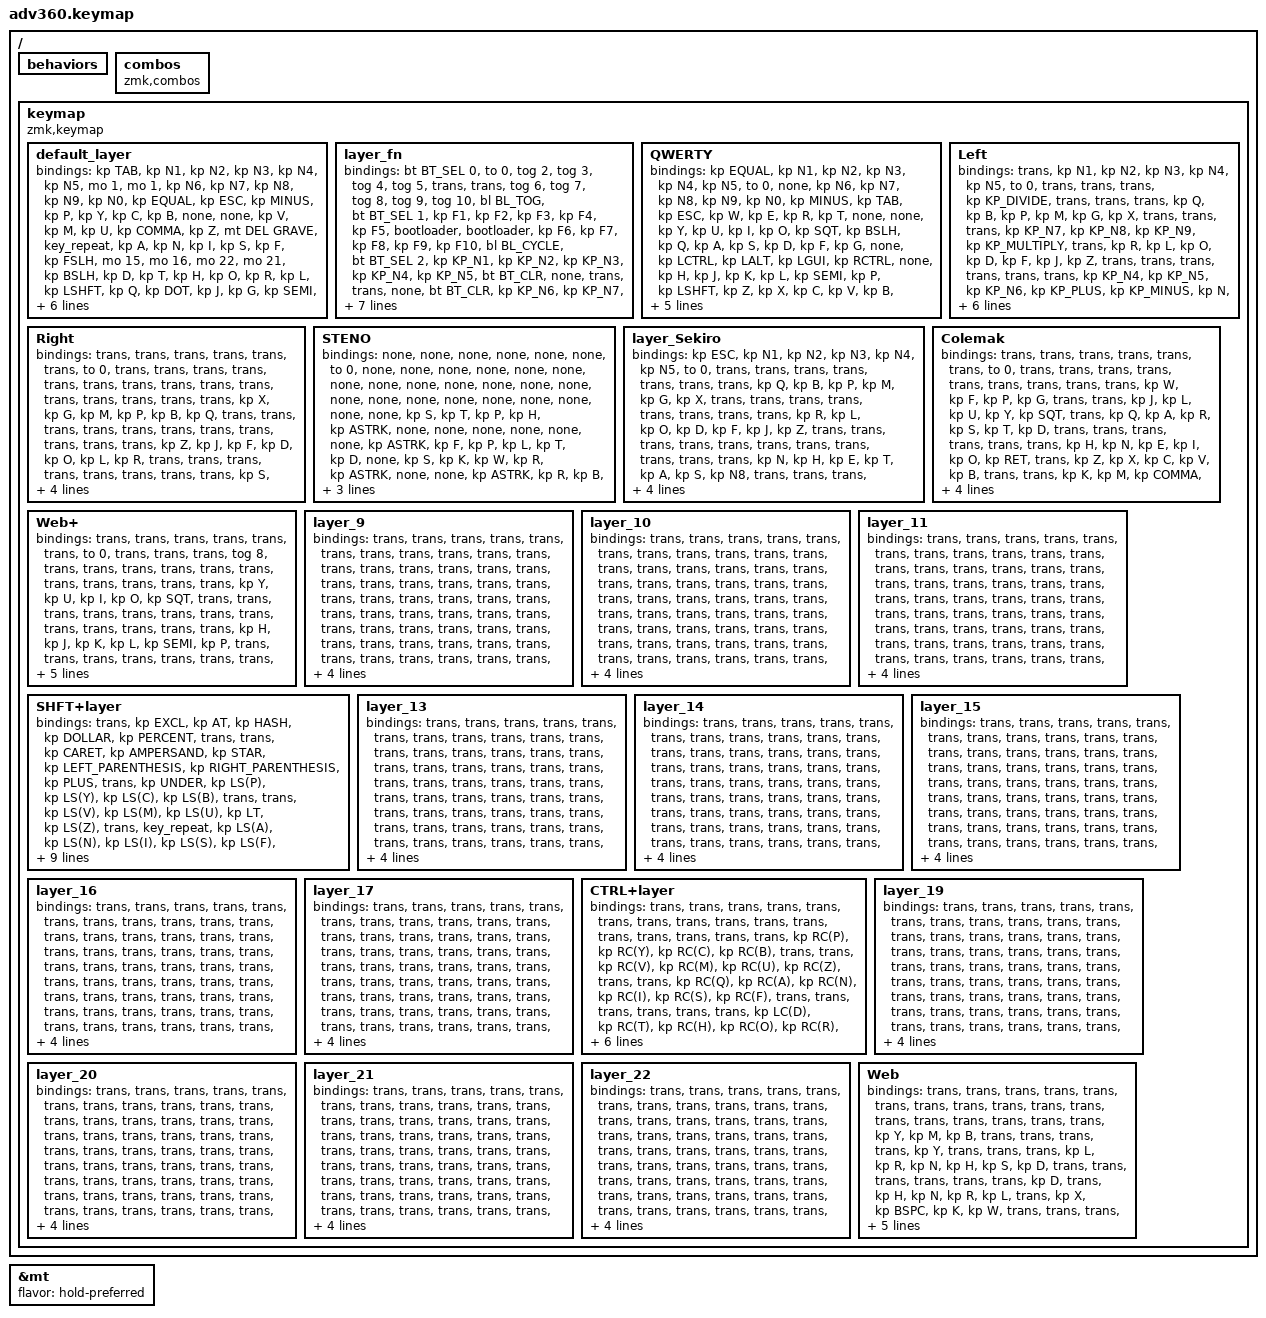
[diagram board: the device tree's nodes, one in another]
/*
 * Copyright (c) 2020 The ZMK Contributors
 *
 * SPDX-License-Identifier: MIT
 */
/* THIS FILE WAS GENERATED!
 *
 * This file was generated automatically. You may or may not want to
 * edit it directly.
 */

#include <behaviors.dtsi>
#include <dt-bindings/zmk/backlight.h>
#include <dt-bindings/zmk/bt.h>
#include <dt-bindings/zmk/keys.h>
#include <dt-bindings/zmk/rgb.h>

&mt { flavor = "hold-preferred"; };

/ {
    behaviors {
        #include "macros.dtsi"
    };

    combos { compatible = "zmk,combos"; };

    keymap {
        compatible = "zmk,keymap";

        default_layer {
            bindings = <
&kp TAB      &kp N1     &kp N2     &kp N3     &kp N4  &kp N5    &mo 1                                                                  &mo 1      &kp N6            &kp N7    &kp N8  &kp N9         &kp N0     &kp EQUAL
&kp ESC      &kp MINUS  &kp P      &kp Y      &kp C   &kp B     &none                                                                  &none      &kp V             &kp M     &kp U   &kp COMMA      &kp Z      &mt DEL GRAVE
&key_repeat  &kp A      &kp N      &kp I      &kp S   &kp F     &kp FSLH  &mo 15           &mo 16           &mo 22       &mo 21        &kp BSLH   &kp D             &kp T     &kp H   &kp O          &kp R      &kp L
&kp LSHFT    &kp Q      &kp DOT    &kp J      &kp G   &kp SEMI                             &mo 14           &lt 20 LBKT                           &kp SINGLE_QUOTE  &kp W     &kp K   &kp BACKSPACE  &kp X      &kp HOME
&kp LCTRL    &none      &kp PG_DN  &kp PG_UP  &none             &kp E     &lt 12 QUESTION  &lt 13 EXCL      &lt 19 RBKT  &lt 18 ENTER  &kp SPACE                    &kp LEFT  &kp UP  &kp DOWN       &kp RIGHT  &kp END
            >;
        };

        layer_fn {
            bindings = <
&bt BT_SEL 0  &to 0      &tog 2     &tog 3     &tog 4     &tog 5     &trans                                           &trans       &tog 6     &tog 7     &tog 8     &tog 9     &tog 10    &bl BL_TOG
&bt BT_SEL 1  &kp F1     &kp F2     &kp F3     &kp F4     &kp F5     &bootloader                                      &bootloader  &kp F6     &kp F7     &kp F8     &kp F9     &kp F10    &bl BL_CYCLE
&bt BT_SEL 2  &kp KP_N1  &kp KP_N2  &kp KP_N3  &kp KP_N4  &kp KP_N5  &bt BT_CLR   &none   &trans      &trans  &none   &bt BT_CLR   &kp KP_N6  &kp KP_N7  &kp KP_N8  &kp KP_N9  &kp KP_N0  &rgb_ug RGB_TOG
&bt BT_SEL 3  &kp F11    &kp F12    &kp F13    &kp F14    &kp F15                         &trans      &trans                       &kp F16    &kp F17    &kp F18    &kp F19    &kp F20    &trans
&bt BT_SEL 4  &kp F21    &kp F22    &kp F23    &kp F24               &trans       &trans  &trans      &trans  &trans  &trans                  &trans     &trans     &trans     &trans     &trans
            >;
        };

        QWERTY {
            bindings = <
&kp EQUAL  &kp N1     &kp N2    &kp N3    &kp N4     &kp N5  &to 0                                                    &none      &kp N6  &kp N7  &kp N8     &kp N9      &kp N0    &kp MINUS
&kp TAB    &kp ESC    &kp W     &kp E     &kp R      &kp T   &none                                                    &none      &kp Y   &kp U   &kp I      &kp O       &kp SQT   &kp BSLH
&kp Q      &kp A      &kp S     &kp D     &kp F      &kp G   &none     &kp LCTRL  &kp LALT      &kp LGUI   &kp RCTRL  &none      &kp H   &kp J   &kp K      &kp L       &kp SEMI  &kp P
&kp LSHFT  &kp Z      &kp X     &kp C     &kp V      &kp B                        &kp HOME      &kp PG_UP                        &kp N   &kp M   &kp COMMA  &kp DOT     &kp FSLH  &kp RSHFT
&trans     &kp GRAVE  &kp CAPS  &kp LEFT  &kp RIGHT          &kp BSPC  &kp DEL    &kp END       &kp PG_DN  &kp ENTER  &kp KP_N0          &kp UP  &kp DOWN   &kp KP_DOT  &kp RBKT  &trans
            >;
        };

        Left {
            bindings = <
&trans  &kp N1  &kp N2  &kp N3  &kp N4  &kp N5  &to 0                                                     &trans  &trans      &trans           &kp KP_DIVIDE  &trans      &trans           &trans
&kp Q   &kp B   &kp P   &kp M   &kp G   &kp X   &trans                                                    &trans  &trans      &kp KP_N7        &kp KP_N8      &kp KP_N9   &kp KP_MULTIPLY  &trans
&kp R   &kp L   &kp O   &kp D   &kp F   &kp J   &kp Z            &trans  &trans           &trans  &trans  &trans  &trans      &kp KP_N4        &kp KP_N5      &kp KP_N6   &kp KP_PLUS      &kp KP_MINUS
&kp N   &kp H   &kp E   &kp T   &kp A   &kp S                            &trans           &trans                  &kp KP_NUM  &kp KP_NUMBER_1  &kp KP_N2      &kp KP_N3   &kp KP_ENTER     &trans
&kp V   &kp W   &kp K   &kp C   &kp Y           &mt LSHFT SPACE  &kp I   &mt LCTRL U      &trans  &trans  &trans              &kp KP_N0        &trans         &kp KP_DOT  &trans           &trans
            >;
        };

        Right {
            bindings = <
&trans  &trans  &trans  &trans  &trans  &trans  &to 0                                                 &trans           &trans  &trans  &trans  &trans  &trans  &trans
&trans  &trans  &trans  &trans  &trans  &trans  &trans                                                &trans           &kp X   &kp G   &kp M   &kp P   &kp B   &kp Q
&trans  &trans  &trans  &trans  &trans  &trans  &trans  &trans  &trans      &trans       &trans       &kp Z            &kp J   &kp F   &kp D   &kp O   &kp L   &kp R
&trans  &trans  &trans  &trans  &trans  &trans                  &trans      &trans                                     &kp S   &kp A   &kp T   &kp E   &kp H   &kp N
&trans  &trans  &trans  &trans  &trans          &trans  &trans  &trans      &mt LCTRL U  &mt LSHFT I  &mt ENTER SPACE          &kp Y   &kp C   &kp K   &kp W   &kp V
            >;
        };

        STENO {
            bindings = <
&none  &none  &none  &none  &none  &none      &to 0                                  &none  &none      &none  &none  &none  &none  &none
&none  &none  &none  &none  &none  &none      &none                                  &none  &none      &none  &none  &none  &none  &none
&none  &kp S  &kp T  &kp P  &kp H  &kp ASTRK  &none  &none  &none      &none  &none  &none  &kp ASTRK  &kp F  &kp P  &kp L  &kp T  &kp D
&none  &kp S  &kp K  &kp W  &kp R  &kp ASTRK                &none      &none                &kp ASTRK  &kp R  &kp B  &kp G  &kp S  &kp Z
&none  &none  &none  &none  &none             &kp A  &kp O  &none      &none  &kp E  &kp U             &none  &none  &none  &none  &trans
            >;
        };

        layer_Sekiro {
            bindings = <
&kp ESC  &kp N1  &kp N2  &kp N3  &kp N4  &kp N5  &to 0                                          &trans  &trans  &trans  &trans  &trans  &trans  &trans
&kp Q    &kp B   &kp P   &kp M   &kp G   &kp X   &trans                                         &trans  &trans  &trans  &trans  &trans  &trans  &trans
&kp R    &kp L   &kp O   &kp D   &kp F   &kp J   &kp Z      &trans  &trans      &trans  &trans  &trans  &trans  &trans  &trans  &trans  &trans  &trans
&kp N    &kp H   &kp E   &kp T   &kp A   &kp S                      &kp N8      &trans                  &trans  &trans  &trans  &trans  &trans  &trans
&kp V    &kp W   &kp K   &kp C   &kp Y           &kp SPACE  &kp I   &kp U       &trans  &trans  &trans          &trans  &trans  &trans  &trans  &trans
            >;
        };

        Colemak {
            bindings = <
&trans  &trans  &trans  &trans  &trans  &trans  &to 0                                       &trans  &trans  &trans  &trans     &trans   &trans    &trans
&trans  &trans  &kp W   &kp F   &kp P   &kp G   &trans                                      &trans  &kp J   &kp L   &kp U      &kp Y    &kp SQT   &trans
&kp Q   &kp A   &kp R   &kp S   &kp T   &kp D   &trans  &trans  &trans      &trans  &trans  &trans  &kp H   &kp N   &kp E      &kp I    &kp O     &kp RET
&trans  &kp Z   &kp X   &kp C   &kp V   &kp B                   &trans      &trans                  &kp K   &kp M   &kp COMMA  &kp DOT  &kp SEMI  &trans
&trans  &trans  &trans  &trans  &trans          &trans  &trans  &trans      &trans  &trans  &trans          &trans  &trans     &trans   &trans    &trans
            >;
        };

        Web+ {
            bindings = <
&trans  &trans  &trans  &trans  &trans  &trans  &to 0                                       &trans  &trans    &trans           &tog 8        &trans         &trans       &trans
&trans  &trans  &trans  &trans  &trans  &trans  &trans                                      &trans  &kp Y     &kp U            &kp I         &kp O          &kp SQT      &trans
&trans  &trans  &trans  &trans  &trans  &trans  &trans  &trans  &trans      &trans  &trans  &trans  &kp H     &kp J            &kp K         &kp L          &kp SEMI     &kp P
&trans  &trans  &trans  &trans  &trans  &trans                  &trans      &trans                  &kp HOME  &kp LC(W)        &kp PG_UP     &kp PG_DN      &kp END      &kp LC(LS(T))
&trans  &trans  &trans  &trans  &trans          &trans  &trans  &trans      &trans  &trans  &trans            &kp LC(LS(TAB))  &kp LA(LEFT)  &kp LA(RIGHT)  &kp LC(TAB)  &trans
            >;
        };

        layer_9 {
            bindings = <
&trans  &trans  &trans  &trans  &trans  &trans  &trans                                      &trans  &trans  &trans  &trans  &trans  &trans  &trans
&trans  &trans  &trans  &trans  &trans  &trans  &trans                                      &trans  &trans  &trans  &trans  &trans  &trans  &trans
&trans  &trans  &trans  &trans  &trans  &trans  &trans  &trans  &trans      &trans  &trans  &trans  &trans  &trans  &trans  &trans  &trans  &trans
&trans  &trans  &trans  &trans  &trans  &trans                  &trans      &trans                  &trans  &trans  &trans  &trans  &trans  &trans
&trans  &trans  &trans  &trans  &trans          &trans  &trans  &trans      &trans  &trans  &trans          &trans  &trans  &trans  &trans  &trans
            >;
        };

        layer_10 {
            bindings = <
&trans  &trans  &trans  &trans  &trans  &trans  &trans                                      &trans  &trans  &trans  &trans  &trans  &trans  &trans
&trans  &trans  &trans  &trans  &trans  &trans  &trans                                      &trans  &trans  &trans  &trans  &trans  &trans  &trans
&trans  &trans  &trans  &trans  &trans  &trans  &trans  &trans  &trans      &trans  &trans  &trans  &trans  &trans  &trans  &trans  &trans  &trans
&trans  &trans  &trans  &trans  &trans  &trans                  &trans      &trans                  &trans  &trans  &trans  &trans  &trans  &trans
&trans  &trans  &trans  &trans  &trans          &trans  &trans  &trans      &trans  &trans  &trans          &trans  &trans  &trans  &trans  &trans
            >;
        };

        layer_11 {
            bindings = <
&trans  &trans  &trans  &trans  &trans  &trans  &trans                                      &trans  &trans  &trans  &trans  &trans  &trans  &trans
&trans  &trans  &trans  &trans  &trans  &trans  &trans                                      &trans  &trans  &trans  &trans  &trans  &trans  &trans
&trans  &trans  &trans  &trans  &trans  &trans  &trans  &trans  &trans      &trans  &trans  &trans  &trans  &trans  &trans  &trans  &trans  &trans
&trans  &trans  &trans  &trans  &trans  &trans                  &trans      &trans                  &trans  &trans  &trans  &trans  &trans  &trans
&trans  &trans  &trans  &trans  &trans          &trans  &trans  &trans      &trans  &trans  &trans          &trans  &trans  &trans  &trans  &trans
            >;
        };

        SHFT+layer {
            bindings = <
&trans       &kp EXCL   &kp AT     &kp HASH   &kp DOLLAR  &kp PERCENT  &trans                                                   &trans    &kp CARET          &kp AMPERSAND  &kp STAR   &kp LEFT_PARENTHESIS  &kp RIGHT_PARENTHESIS  &kp PLUS
&trans       &kp UNDER  &kp LS(P)  &kp LS(Y)  &kp LS(C)   &kp LS(B)    &trans                                                   &trans    &kp LS(V)          &kp LS(M)      &kp LS(U)  &kp LT                &kp LS(Z)              &trans
&key_repeat  &kp LS(A)  &kp LS(N)  &kp LS(I)  &kp LS(S)   &kp LS(F)    &kp LS(NON_US_BSLH)  &trans  &trans      &trans  &trans  &kp PIPE  &kp LS(D)          &kp LS(T)      &kp LS(H)  &kp LS(O)             &kp LS(R)              &kp LS(L)
&trans       &kp LS(Q)  &kp GT     &kp LS(J)  &kp LS(G)   &kp COLON                                 &trans      &trans                    &kp DOUBLE_QUOTES  &kp LS(W)      &kp LS(K)  &kp BSPC              &kp LS(X)              &trans
&trans       &trans     &trans     &trans     &trans                   &trans               &trans  &trans      &trans  &trans  &trans                       &trans         &trans     &trans                &trans                 &trans
            >;
        };

        layer_13 {
            bindings = <
&trans  &trans  &trans  &trans  &trans  &trans  &trans                                      &trans  &trans  &trans  &trans  &trans  &trans  &trans
&trans  &trans  &trans  &trans  &trans  &trans  &trans                                      &trans  &trans  &trans  &trans  &trans  &trans  &trans
&trans  &trans  &trans  &trans  &trans  &trans  &trans  &trans  &trans      &trans  &trans  &trans  &trans  &trans  &trans  &trans  &trans  &trans
&trans  &trans  &trans  &trans  &trans  &trans                  &trans      &trans                  &trans  &trans  &trans  &trans  &trans  &trans
&trans  &trans  &trans  &trans  &trans          &trans  &trans  &trans      &trans  &trans  &trans          &trans  &trans  &trans  &trans  &trans
            >;
        };

        layer_14 {
            bindings = <
&trans  &trans  &trans  &trans  &trans  &trans  &trans                                      &trans  &trans  &trans  &trans  &trans  &trans  &trans
&trans  &trans  &trans  &trans  &trans  &trans  &trans                                      &trans  &trans  &trans  &trans  &trans  &trans  &trans
&trans  &trans  &trans  &trans  &trans  &trans  &trans  &trans  &trans      &trans  &trans  &trans  &trans  &trans  &trans  &trans  &trans  &trans
&trans  &trans  &trans  &trans  &trans  &trans                  &trans      &trans                  &trans  &trans  &trans  &trans  &trans  &trans
&trans  &trans  &trans  &trans  &trans          &trans  &trans  &trans      &trans  &trans  &trans          &trans  &trans  &trans  &trans  &trans
            >;
        };

        layer_15 {
            bindings = <
&trans  &trans  &trans  &trans  &trans  &trans  &trans                                      &trans  &trans  &trans  &trans  &trans  &trans  &trans
&trans  &trans  &trans  &trans  &trans  &trans  &trans                                      &trans  &trans  &trans  &trans  &trans  &trans  &trans
&trans  &trans  &trans  &trans  &trans  &trans  &trans  &trans  &trans      &trans  &trans  &trans  &trans  &trans  &trans  &trans  &trans  &trans
&trans  &trans  &trans  &trans  &trans  &trans                  &trans      &trans                  &trans  &trans  &trans  &trans  &trans  &trans
&trans  &trans  &trans  &trans  &trans          &trans  &trans  &trans      &trans  &trans  &trans          &trans  &trans  &trans  &trans  &trans
            >;
        };

        layer_16 {
            bindings = <
&trans  &trans  &trans  &trans  &trans  &trans  &trans                                      &trans  &trans  &trans  &trans  &trans  &trans  &trans
&trans  &trans  &trans  &trans  &trans  &trans  &trans                                      &trans  &trans  &trans  &trans  &trans  &trans  &trans
&trans  &trans  &trans  &trans  &trans  &trans  &trans  &trans  &trans      &trans  &trans  &trans  &trans  &trans  &trans  &trans  &trans  &trans
&trans  &trans  &trans  &trans  &trans  &trans                  &trans      &trans                  &trans  &trans  &trans  &trans  &trans  &trans
&trans  &trans  &trans  &trans  &trans          &trans  &trans  &trans      &trans  &trans  &trans          &trans  &trans  &trans  &trans  &trans
            >;
        };

        layer_17 {
            bindings = <
&trans  &trans  &trans  &trans  &trans  &trans  &trans                                      &trans  &trans  &trans  &trans  &trans  &trans  &trans
&trans  &trans  &trans  &trans  &trans  &trans  &trans                                      &trans  &trans  &trans  &trans  &trans  &trans  &trans
&trans  &trans  &trans  &trans  &trans  &trans  &trans  &trans  &trans      &trans  &trans  &trans  &trans  &trans  &trans  &trans  &trans  &trans
&trans  &trans  &trans  &trans  &trans  &trans                  &trans      &trans                  &trans  &trans  &trans  &trans  &trans  &trans
&trans  &trans  &trans  &trans  &trans          &trans  &trans  &trans      &trans  &trans  &trans          &trans  &trans  &trans  &trans  &trans
            >;
        };

        CTRL+layer {
            bindings = <
&trans     &trans         &trans       &trans     &trans     &trans        &trans                                      &trans  &trans     &trans     &trans     &trans     &trans     &trans
&trans     &trans         &kp RC(P)    &kp RC(Y)  &kp RC(C)  &kp RC(B)     &trans                                      &trans  &kp RC(V)  &kp RC(M)  &kp RC(U)  &kp RC(Z)  &trans     &trans
&kp RC(Q)  &kp RC(A)      &kp RC(N)    &kp RC(I)  &kp RC(S)  &kp RC(F)     &trans  &trans  &trans      &trans  &trans  &trans  &kp LC(D)  &kp RC(T)  &kp RC(H)  &kp RC(O)  &kp RC(R)  &kp RC(L)
&trans     &kp RC(COMMA)  &kp RC(DOT)  &kp RC(J)  &kp RC(G)  &kp RC(SEMI)                  &trans      &trans                  &trans     &kp RC(W)  &kp RC(K)  &trans     &kp RC(X)  &trans
&trans     &trans         &trans       &trans     &trans                   &trans  &trans  &trans      &trans  &trans  &trans             &trans     &trans     &trans     &trans     &trans
            >;
        };

        layer_19 {
            bindings = <
&trans  &trans  &trans  &trans  &trans  &trans  &trans                                      &trans  &trans  &trans  &trans  &trans  &trans  &trans
&trans  &trans  &trans  &trans  &trans  &trans  &trans                                      &trans  &trans  &trans  &trans  &trans  &trans  &trans
&trans  &trans  &trans  &trans  &trans  &trans  &trans  &trans  &trans      &trans  &trans  &trans  &trans  &trans  &trans  &trans  &trans  &trans
&trans  &trans  &trans  &trans  &trans  &trans                  &trans      &trans                  &trans  &trans  &trans  &trans  &trans  &trans
&trans  &trans  &trans  &trans  &trans          &trans  &trans  &trans      &trans  &trans  &trans          &trans  &trans  &trans  &trans  &trans
            >;
        };

        layer_20 {
            bindings = <
&trans  &trans  &trans  &trans  &trans  &trans  &trans                                      &trans  &trans  &trans  &trans  &trans  &trans  &trans
&trans  &trans  &trans  &trans  &trans  &trans  &trans                                      &trans  &trans  &trans  &trans  &trans  &trans  &trans
&trans  &trans  &trans  &trans  &trans  &trans  &trans  &trans  &trans      &trans  &trans  &trans  &trans  &trans  &trans  &trans  &trans  &trans
&trans  &trans  &trans  &trans  &trans  &trans                  &trans      &trans                  &trans  &trans  &trans  &trans  &trans  &trans
&trans  &trans  &trans  &trans  &trans          &trans  &trans  &trans      &trans  &trans  &trans          &trans  &trans  &trans  &trans  &trans
            >;
        };

        layer_21 {
            bindings = <
&trans  &trans  &trans  &trans  &trans  &trans  &trans                                      &trans  &trans  &trans  &trans  &trans  &trans  &trans
&trans  &trans  &trans  &trans  &trans  &trans  &trans                                      &trans  &trans  &trans  &trans  &trans  &trans  &trans
&trans  &trans  &trans  &trans  &trans  &trans  &trans  &trans  &trans      &trans  &trans  &trans  &trans  &trans  &trans  &trans  &trans  &trans
&trans  &trans  &trans  &trans  &trans  &trans                  &trans      &trans                  &trans  &trans  &trans  &trans  &trans  &trans
&trans  &trans  &trans  &trans  &trans          &trans  &trans  &trans      &trans  &trans  &trans          &trans  &trans  &trans  &trans  &trans
            >;
        };

        layer_22 {
            bindings = <
&trans  &trans  &trans  &trans  &trans  &trans  &trans                                      &trans  &trans  &trans  &trans  &trans  &trans  &trans
&trans  &trans  &trans  &trans  &trans  &trans  &trans                                      &trans  &trans  &trans  &trans  &trans  &trans  &trans
&trans  &trans  &trans  &trans  &trans  &trans  &trans  &trans  &trans      &trans  &trans  &trans  &trans  &trans  &trans  &trans  &trans  &trans
&trans  &trans  &trans  &trans  &trans  &trans                  &trans      &trans                  &trans  &trans  &trans  &trans  &trans  &trans
&trans  &trans  &trans  &trans  &trans          &trans  &trans  &trans      &trans  &trans  &trans          &trans  &trans  &trans  &trans  &trans
            >;
        };

        Web {
            bindings = <
&trans  &trans    &trans    &trans    &trans     &trans  &trans                                            &trans              &trans  &trans    &trans  &trans    &trans     &trans
&trans  &trans    &trans    &kp Y     &kp M      &kp B   &trans                                            &trans              &trans  &trans    &kp Y   &trans    &trans     &trans
&kp L   &kp R     &kp N     &kp H     &kp S      &kp D   &trans  &trans  &trans      &trans  &trans        &trans              &kp D   &trans    &kp H   &kp N     &kp R      &kp L
&trans  &kp X     &kp BSPC  &kp K     &kp W      &trans                  &trans      &trans                                    &trans  &kp W     &kp K   &kp BSPC  &kp X      &trans
&trans  &kp LEFT  &kp UP    &kp DOWN  &kp RIGHT          &trans  &trans  &trans      &trans  &lt 18 ENTER  &lt 8 K_PLAY_PAUSE          &kp LEFT  &kp UP  &kp DOWN  &kp RIGHT  &trans
            >;
        };
    };
};
